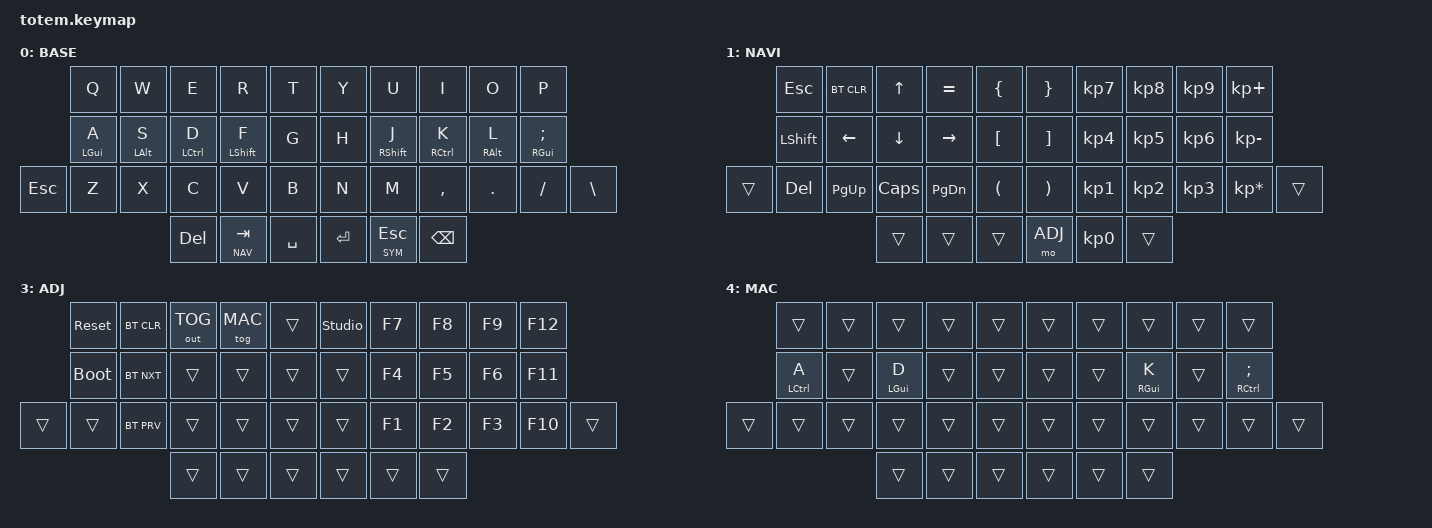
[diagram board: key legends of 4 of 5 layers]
//
//                                                        ▀▀▀▀▀     ▀▀▀▀▀          ▀▀█▀▀
//                                                        ▄▀▀▀▄  ▄  ▄▀▀▀▄  ▄  ▄▀▀▀▄  █  ▄▀▀▀▄
//                                                        █   █  █  █   █  █  █   █  █  █   █
//                                                         ▀▀▀   █   ▀▀▀   █   ▀▀▀   ▀   ▀▀▀
//                                                               █      ▄▄▄█▄▄▄    █   █
//                                                               ▀      █  █  █     █▄█
//                                                             ▀▀▀▀▀    █  █  █      ▀
//                                                                      ▀  ▀  ▀
//
// ─────────────────────────────────────────────────────────────────────────────────────────────────
// User-override keymap (QWERTY + home-row mods + MAC layer).
// This lives in config/ and takes precedence over the shield-directory keymap
// when ZMK's CMake finds it first in its lookup order.
// ─────────────────────────────────────────────────────────────────────────────────────────────────

#include <behaviors.dtsi>
#include <dt-bindings/zmk/keys.h>
#include <dt-bindings/zmk/bt.h>
#include <dt-bindings/zmk/outputs.h>

#define BASE 0
#define NAV  1
#define SYM  2
#define ADJ  3
#define MAC  4

&mt {
  quick-tap-ms = <100>;
  global-quick-tap;
  flavor = "tap-preferred";
  tapping-term-ms = <170>;
};

/ {
     combos {
            compatible = "zmk,combos";
            combo_esc {
                timeout-ms = <50>;
                key-positions = <0 1>;
                bindings = <&kp ESC>;
            };
    };

        keymap {
                compatible = "zmk,keymap";
// ─────────────────────────────────────────────────────────────────────────────────────────────────

                base_layer {
label= "BASE";
//             ┏━━━━━━━━━━━┳━━━━━━━━━━━┳━━━━━━━━━━━┳━━━━━━━━━━━┳━━━━━━━━━━━┓   ┏━━━━━━━━━━━┳━━━━━━━━━━━┳━━━━━━━━━━━┳━━━━━━━━━━━┳━━━━━━━━━━━┓
//             ┃     Q     ┃     W     ┃     E     ┃     R     ┃     T     ┃   ┃     Y     ┃     U     ┃     I     ┃     O     ┃     P     ┃
//             ┣━━━━━━━━━━━╋━━━━━━━━━━━╋━━━━━━━━━━━╋━━━━━━━━━━━╋━━━━━━━━━━━┫   ┣━━━━━━━━━━━╋━━━━━━━━━━━╋━━━━━━━━━━━╋━━━━━━━━━━━╋━━━━━━━━━━━┫
//             ┃ GUI/  A   ┃ ALT/  S   ┃ CTRL/ D   ┃ SHFT/ F   ┃     G     ┃   ┃     H     ┃ SHFT/ J   ┃ CTRL/ K   ┃ ALT/  L   ┃ GUI/  ;   ┃
// ┏━━━━━━━━━━━╋━━━━━━━━━━━╋━━━━━━━━━━━╋━━━━━━━━━━━╋━━━━━━━━━━━╋━━━━━━━━━━━┫   ┣━━━━━━━━━━━╋━━━━━━━━━━━╋━━━━━━━━━━━╋━━━━━━━━━━━╋━━━━━━━━━━━╋━━━━━━━━━━━┓
// ┃    ESC    ┃     Z     ┃     X     ┃     C     ┃     V     ┃     B     ┃   ┃     N     ┃     M     ┃     ,     ┃     .     ┃     /     ┃     \     ┃
// ┗━━━━━━━━━━━┻━━━━━━━━━━━┻━━━━━━━━━━━╋━━━━━━━━━━━╋━━━━━━━━━━━╋━━━━━━━━━━━┫   ┣━━━━━━━━━━━╋━━━━━━━━━━━╋━━━━━━━━━━━╋━━━━━━━━━━━┻━━━━━━━━━━━┻━━━━━━━━━━━┛
//                                     ┃    DEL    ┃ NAV / TAB ┃    SPC    ┃   ┃   ENTER   ┃ SYM / ESC ┃   BSPC    ┃
//                                     ┗━━━━━━━━━━━┻━━━━━━━━━━━┻━━━━━━━━━━━┛   ┗━━━━━━━━━━━┻━━━━━━━━━━━┻━━━━━━━━━━━┛
 bindings = <
                &kp Q       &kp W       &kp E       &kp R       &kp T           &kp Y       &kp U       &kp I       &kp O       &kp P
                &mt LGUI A  &mt LALT S  &mt LCTRL D &mt LSHFT F &kp G           &kp H       &mt RSHFT J &mt RCTRL K &mt RALT L  &mt RGUI SEMI
    &kp ESC     &kp Z       &kp X       &kp C       &kp V       &kp B           &kp N       &kp M       &kp COMMA   &kp DOT     &kp FSLH    &kp BSLH
                                        &kp DEL   &lt NAV TAB   &kp SPACE       &kp RET   &lt SYM ESC   &kp BSPC
                        >;
                };

// ─────────────────────────────────────────────────────────────────────────────────────────────────

                nav_layer {
label= "NAVI";
 bindings = <
                &kp ESC     &bt BT_CLR  &kp UP      &kp EQUAL   &kp LBRC        &kp RBRC    &kp KP_N7   &kp KP_N8   &kp KP_N9   &kp KP_PLUS
                &kp LSHFT   &kp LEFT    &kp DOWN    &kp RIGHT   &kp LBKT        &kp RBKT    &kp KP_N4   &kp KP_N5   &kp KP_N6   &kp KP_MINUS
    &trans      &kp DEL     &kp PG_UP   &kp CAPS    &kp PG_DN   &kp LPAR        &kp RPAR    &kp KP_N1   &kp KP_N2   &kp KP_N3   &kp KP_MULTIPLY &trans
                                        &trans      &trans      &trans          &mo ADJ     &kp KP_N0   &trans
                        >;
                };

// ─────────────────────────────────────────────────────────────────────────────────────────────────

                sim_layer {
label= "SYM";
 bindings = <
                &kp EXCL    &kp AT      &kp HASH    &kp DLLR    &kp PRCNT       &kp CARET   &kp AMPS    &kp STAR    &kp LPAR    &kp RPAR
                &kp GRAVE   &kp MINUS   &kp UNDER   &kp EQUAL   &kp LBKT        &kp RBKT    &kp BSLH    &kp SEMI    &kp SQT     &kp DQT
    &kp POUND  &trans      &trans      &trans      &trans          &kp C_VOL_DN &kp C_VOL_UP &kp C_PREV &kp C_NEXT  &kp PIPE    &trans
                                        &trans      &mo ADJ     &trans          &kp C_MUTE  &kp C_PP    &trans
                        >;
                };

// ─────────────────────────────────────────────────────────────────────────────────────────────────

                adjust_layer {
label= "ADJ";
//
// BT_NXT / BT_PRV — cycle through Bluetooth host profiles (0-4, up to 5 hosts)
// BT_CLR          — clear current profile pairing (use before re-pairing)
// OUT_TOG         — toggle HID output USB ↔ BLE
// tog MAC         — toggle the MAC layer (swaps GUI/CTRL on home row)
//
 bindings = <
                &sys_reset  &bt BT_CLR &out OUT_TOG &tog MAC    &trans          &studio_unlock &kp F7   &kp F8      &kp F9      &kp F12
                &bootloader &bt BT_NXT  &trans      &trans      &trans          &trans      &kp F4      &kp F5      &kp F6      &kp F11
    &trans      &trans      &bt BT_PRV  &trans      &trans      &trans          &trans      &kp F1      &kp F2      &kp F3      &kp F10     &trans
                                        &trans      &trans      &trans          &trans      &trans      &trans
                        >;
                };

// ─────────────────────────────────────────────────────────────────────────────────────────────────

                mac_layer {
label= "MAC";
// Swaps GUI and CTRL on the home row for macOS (Cmd replaces Ctrl).
 bindings = <
                &trans      &trans      &trans      &trans      &trans          &trans      &trans      &trans      &trans      &trans
                &mt LCTRL A &trans      &mt LGUI D  &trans      &trans          &trans      &trans      &mt RGUI K  &trans      &mt RCTRL SEMI
    &trans      &trans      &trans      &trans      &trans      &trans          &trans      &trans      &trans      &trans      &trans      &trans
                                        &trans      &trans      &trans          &trans      &trans      &trans
                        >;
                };
        };
};
